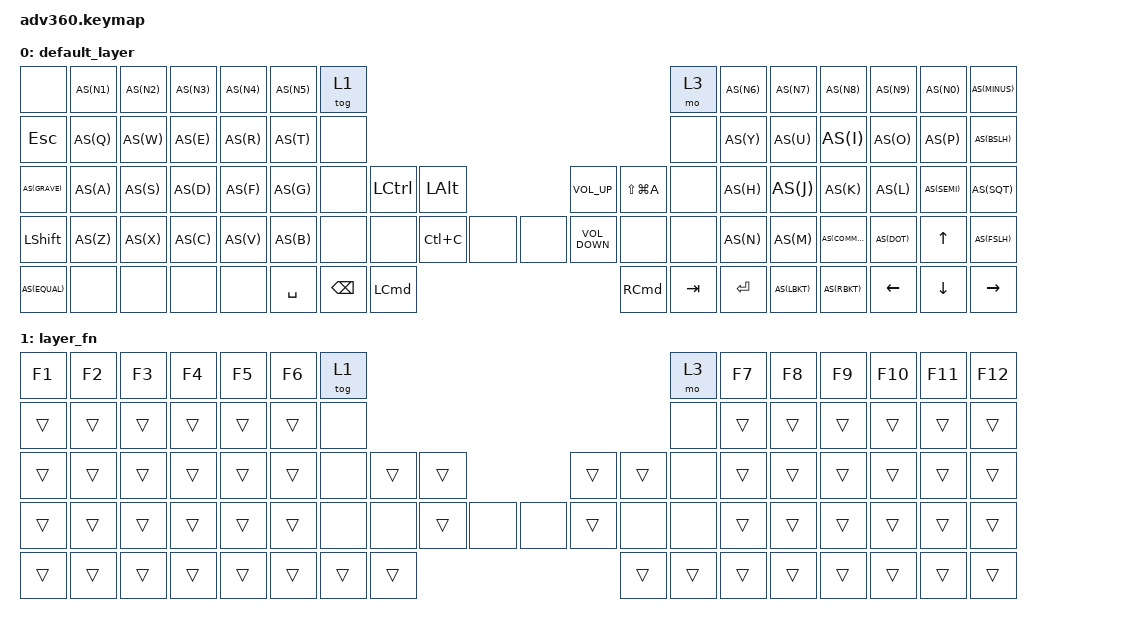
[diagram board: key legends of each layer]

/*
 * Copyright (c) 2020 The ZMK Contributors
 *
 * SPDX-License-Identifier: MIT
 */


#include <behaviors.dtsi>
#include <dt-bindings/zmk/keys.h>

#define AS(keycode) &as LS(keycode) keycode     // Autoshift Macro

/ {
    behaviors { 
        as: auto_shift {
            compatible = "zmk,behavior-hold-tap";
            label = "AUTO_SHIFT";
            #binding-cells = <2>;
            tapping-term-ms = <200>;
            quick-tap-ms = <0>;
            flavor = "tap-preferred";
            bindings = <&kp>, <&kp>;
        };
    };

    keymap {
        compatible = "zmk,keymap";
        default_layer {
            bindings = <
                &none         AS(N1)    AS(N2)    AS(N3)     AS(N4)     AS(N5)      &tog 1                                                                                                                              &mo 3   AS(N6)    AS(N7)     AS(N8)     AS(N9)      AS(N0)      AS(MINUS)
                &kp ESCAPE    AS(Q)     AS(W)     AS(E)      AS(R)      AS(T)       &none                                                                                                                               &none   AS(Y)     AS(U)      AS(I)      AS(O)       AS(P)       AS(BSLH)
                AS(GRAVE)     AS(A)     AS(S)     AS(D)      AS(F)      AS(G)       &none                        &kp LCTRL       &kp LALT                   &kp C_VOLUME_UP       &kp LS(LG(A))                         &none   AS(H)     AS(J)      AS(K)      AS(L)       AS(SEMI)    AS(SQT)
                &kp LSHFT     AS(Z)     AS(X)     AS(C)      AS(V)      AS(B)       &none &none                                  &kp LC(C)  &none  &none    &kp C_VOLUME_DOWN                                    &none  &none   AS(N)     AS(M)      AS(COMMA)  AS(DOT)     &kp UP      AS(FSLH)
                AS(EQUAL)     &none     &none     &none      &none                                  &kp SPACE    &kp BACKSPACE   &kp LCMD                   &kp RCMD              &kp TAB           &kp ENTER                             AS(LBKT)   AS(RBKT)   &kp LEFT    &kp DOWN    &kp RIGHT
            >;
        };

        layer_fn {
            bindings = <
 &kp F1  &kp F2  &kp F3  &kp F4  &kp F5  &kp F6            &tog 1                                                   &mo 3  &kp F7  &kp F8  &kp F9  &kp F10  &kp F11  &kp F12
 &trans  &trans  &trans  &trans  &trans  &trans             &none                                                   &none  &trans  &trans  &trans   &trans   &trans   &trans
 &trans  &trans  &trans  &trans  &trans  &trans             &none  &trans  &trans                  &trans  &trans   &none  &trans  &trans  &trans   &trans   &trans   &trans
 &trans  &trans  &trans  &trans  &trans  &trans             &none   &none  &trans   &none   &none  &trans   &none   &none  &trans  &trans  &trans   &trans   &trans   &trans
 &trans  &trans  &trans  &trans  &trans                    &trans  &trans  &trans                  &trans  &trans  &trans          &trans  &trans   &trans   &trans   &trans
            >;
        };

    };
};
